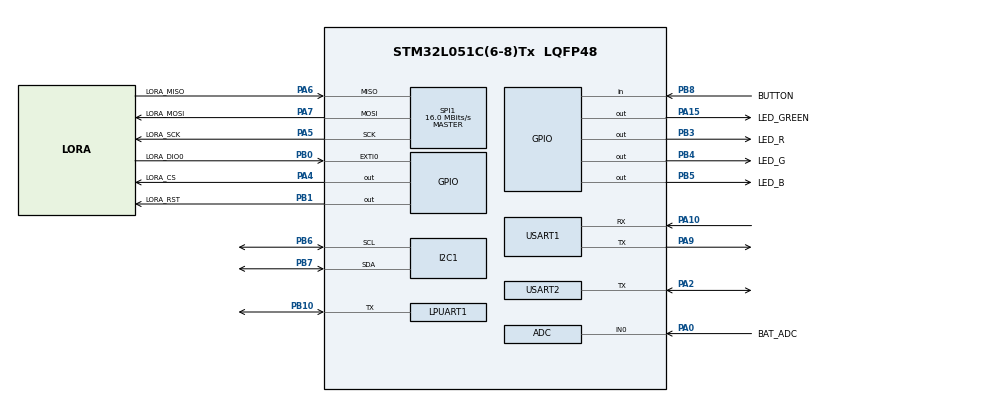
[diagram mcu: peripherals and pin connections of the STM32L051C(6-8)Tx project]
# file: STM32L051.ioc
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ADC.SamplingTime=ADC_SAMPLETIME_79CYCLES_5
I2C1.Timing=0x00B07CB4
LPUART1.BaudRate=115200
LPUART1.WordLength=UART_WORDLENGTH_8B
Mcu.Family=STM32L0
Mcu.Name=STM32L051C(6-8)Tx
Mcu.Package=LQFP48
NVIC.ADC1_COMP_IRQn=true\:0\:0\:false\:false\:true\:true\:true\:true
NVIC.EXTI0_1_IRQn=true\:0\:0\:false\:false\:true\:true\:true\:true
NVIC.RTC_IRQn=true\:0\:0\:false\:false\:true\:true\:true\:true
NVIC.SPI1_IRQn=true\:0\:0\:false\:false\:true\:true\:true\:true
PA0.GPIO_Label=BAT_ADC
PA0.Mode=IN0
PA0.Signal=ADC_IN0
PA10.Mode=Asynchronous
PA10.Signal=USART1_RX
PA13.Mode=Serial_Wire
PA13.Signal=SYS_SWDIO
PA14.Mode=Serial_Wire
PA14.Signal=SYS_SWCLK
PA15.GPIO_Label=LED_GREEN
PA15.Signal=GPIO_Output
PA2.Mode=Half_duplex(single_wire_mode)
PA2.Signal=USART2_TX
PA4.GPIO_Label=LORA_CS
PA4.Signal=GPIO_Output
PA5.GPIO_Label=LORA_SCK
PA5.Mode=Full_Duplex_Master
PA5.Signal=SPI1_SCK
PA6.GPIO_Label=LORA_MISO
PA6.Mode=Full_Duplex_Master
PA6.Signal=SPI1_MISO
PA7.GPIO_Label=LORA_MOSI
PA7.Mode=Full_Duplex_Master
PA7.Signal=SPI1_MOSI
PA9.Mode=Asynchronous
PA9.Signal=USART1_TX
PB0.GPIO_Label=LORA_DIO0
PB0.Signal=GPXTI0
PB1.GPIO_Label=LORA_RST
PB1.Signal=GPIO_Output
PB10.Mode=Half_duplex(single_wire_mode)
PB10.Signal=LPUART1_TX
PB12.Signal=SPI2_NSS
PB13.Signal=SPI2_SCK
PB14.Signal=SPI2_MISO
PB15.Signal=SPI2_MOSI
PB3.GPIO_Label=LED_R
PB3.Signal=GPIO_Output
PB4.GPIO_Label=LED_G
PB4.Signal=GPIO_Output
PB5.GPIO_Label=LED_B
PB5.Signal=GPIO_Output
PB6.Mode=I2C
PB6.Signal=I2C1_SCL
PB7.Mode=I2C
PB7.Signal=I2C1_SDA
PB8.GPIO_Label=BUTTON
PB8.Signal=GPIO_Input
ProjectManager.HeapSize=0x64
ProjectManager.StackSize=0x200
ProjectManager.TargetToolchain=STM32CubeIDE
RCC.AHBFreq_Value=32000000
RCC.APB1Freq_Value=32000000
RCC.APB1TimFreq_Value=32000000
RCC.APB2Freq_Value=32000000
RCC.APB2TimFreq_Value=32000000
RCC.HCLKFreq_Value=32000000
RCC.HSE_VALUE=8000000
RCC.HSI16_VALUE=16000000
RCC.HSI_VALUE=16000000
RCC.LSE_VALUE=32768
RCC.MSI_VALUE=2097000
RCC.PLLMUL=RCC_PLLMUL_4
RCC.SYSCLKFreq_VALUE=32000000
RCC.SYSCLKSource=RCC_SYSCLKSOURCE_PLLCLK
RCC.VCOOutputFreq_Value=64000000
RTC.WakeUpClock-WakeUp=RTC_WAKEUPCLOCK_RTCCLK_DIV2
RTC.WakeUpCounter-WakeUp=1200
SPI1.CalculateBaudRate=16.0 MBits/s
SPI1.Direction=SPI_DIRECTION_2LINES
SPI1.Mode=SPI_MODE_MASTER
SPI1.VirtualType=VM_MASTER
USART1.VirtualMode-Asynchronous=VM_ASYNC
USART2.VirtualMode-Half_duplex(single_wire_mode)=VM_ASYNC
VP_ADC_TempSens_Input.Mode=IN-TempSens
VP_ADC_Vref_Input.Mode=IN-Vrefint
VP_RTC_VS_RTC_Activate.Mode=RTC_Enabled
VP_RTC_VS_RTC_WakeUp_intern.Mode=WakeUp
board=custom

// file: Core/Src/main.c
/* USER CODE BEGIN Header */
/**
  ******************************************************************************
  * @file           : main.c
  * @brief          : Main program body
  ******************************************************************************
  * @attention
  *
  * Copyright (c) 2024 STMicroelectronics.
  * All rights reserved.
  *
  * This software is licensed under terms that can be found in the LICENSE file
  * in the root directory of this software component.
  * If no LICENSE file comes with this software, it is provided AS-IS.
  *
  ******************************************************************************
  */
/* USER CODE END Header */
#include "main.h"
#include "adc.h"
#include "i2c.h"
#include "usart.h"
#include "rtc.h"
#include "spi.h"
#include "gpio.h"

/* USER CODE BEGIN Includes */
#include "project.h"
/* USER CODE END Includes */

void SystemClock_Config(void);

int main(void)
{

  /* MCU Configuration--------------------------------------------------------*/

  /* Reset of all peripherals, Initializes the Flash interface and the Systick. */
  HAL_Init();

  /* Configure the system clock */
  SystemClock_Config();

  /* USER CODE BEGIN SysInit */
  LL_SYSTICK_EnableIT();
  /* USER CODE END SysInit */

  /* Initialize all configured peripherals */
  MX_GPIO_Init();
  MX_I2C1_Init();
  MX_USART1_UART_Init();
  MX_SPI1_Init();
  MX_RTC_Init();
  MX_ADC_Init();
  MX_USART2_UART_Init();
  MX_LPUART1_UART_Init();
  /* USER CODE BEGIN 2 */
  project_main();
  /* USER CODE END 2 */

  /* Infinite loop */
  while (1)
  {

  }
}

void SystemClock_Config(void)
{
  LL_FLASH_SetLatency(LL_FLASH_LATENCY_1);
  while(LL_FLASH_GetLatency()!= LL_FLASH_LATENCY_1)
  {
  }
  LL_PWR_SetRegulVoltageScaling(LL_PWR_REGU_VOLTAGE_SCALE1);
  while (LL_PWR_IsActiveFlag_VOS() != 0)
  {
  }
  LL_RCC_HSI_Enable();

   /* Wait till HSI is ready */
  while(LL_RCC_HSI_IsReady() != 1)
  {

  }
  LL_RCC_HSI_SetCalibTrimming(16);
  LL_RCC_LSI_Enable();

   /* Wait till LSI is ready */
  while(LL_RCC_LSI_IsReady() != 1)
  {

  }
  LL_PWR_EnableBkUpAccess();
  if(LL_RCC_GetRTCClockSource() != LL_RCC_RTC_CLKSOURCE_LSI)
  {
    LL_RCC_ForceBackupDomainReset();
    LL_RCC_ReleaseBackupDomainReset();
    LL_RCC_SetRTCClockSource(LL_RCC_RTC_CLKSOURCE_LSI);
  }
  LL_RCC_EnableRTC();
  LL_RCC_PLL_ConfigDomain_SYS(LL_RCC_PLLSOURCE_HSI, LL_RCC_PLL_MUL_4, LL_RCC_PLL_DIV_2);
  LL_RCC_PLL_Enable();

   /* Wait till PLL is ready */
  while(LL_RCC_PLL_IsReady() != 1)
  {

  }
  LL_RCC_SetAHBPrescaler(LL_RCC_SYSCLK_DIV_1);
  LL_RCC_SetAPB1Prescaler(LL_RCC_APB1_DIV_1);
  LL_RCC_SetAPB2Prescaler(LL_RCC_APB2_DIV_1);
  LL_RCC_SetSysClkSource(LL_RCC_SYS_CLKSOURCE_PLL);

   /* Wait till System clock is ready */
  while(LL_RCC_GetSysClkSource() != LL_RCC_SYS_CLKSOURCE_STATUS_PLL)
  {

  }
  LL_SetSystemCoreClock(32000000);

   /* Update the time base */
  if (HAL_InitTick (TICK_INT_PRIORITY) != HAL_OK)
  {
    Error_Handler();
  }
  LL_RCC_SetUSARTClockSource(LL_RCC_USART1_CLKSOURCE_PCLK2);
  LL_RCC_SetUSARTClockSource(LL_RCC_USART2_CLKSOURCE_PCLK1);
  LL_RCC_SetLPUARTClockSource(LL_RCC_LPUART1_CLKSOURCE_PCLK1);
  LL_RCC_SetI2CClockSource(LL_RCC_I2C1_CLKSOURCE_PCLK1);
}

void Error_Handler(void)
{
  __disable_irq();
  while (1)
  {
  }
}
